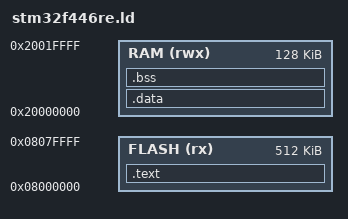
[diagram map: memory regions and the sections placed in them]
/* Minimal linker script for STM32F446RE */
MEMORY
{
  FLASH (rx) : ORIGIN = 0x08000000, LENGTH = 512K
  RAM (rwx)  : ORIGIN = 0x20000000, LENGTH = 128K
}

SECTIONS
{
  .text :
  {
    KEEP(*(.isr_vector))
    *(.text*)
    *(.rodata*)
    _etext = .;
  } > FLASH

  .data : AT (ADDR(.text) + SIZEOF(.text))
  {
    _sdata = .;
    *(.data*)
    _edata = .;
  } > RAM

  .bss :
  {
    _sbss = .;
    *(.bss*)
    *(COMMON)
    _ebss = .;
  } > RAM

  . = ALIGN(4);
  end = .;
}

